# RE01_256KB register map
Vendor: Renesas Electronics Corporation; Series: RE01; File version: 1.00.01
CPU: CM0PLUS r0p1, little endian, MPU, no FPU, VTOR, 2 interrupt priority bits, 32 interrupts
Registers are 8-bit, read-write, reset 0x0 unless marked. A register's access mark holds for its fields unless they carry their own. Offsets are from the block's base; [hi:lo] are bit positions; {n}, {i} and the like mark numbered series; 'fields as' and 'values as' point back to an identical list; <NAME> marks a mode.

## SYSC — System Control
Base 0x4001E000
0x0C SBYCR 16-bit — Standby Control Register
  [15] SSBY — Software Standby Mode Select
    0=Sleep mode; 1=Software Standby mode
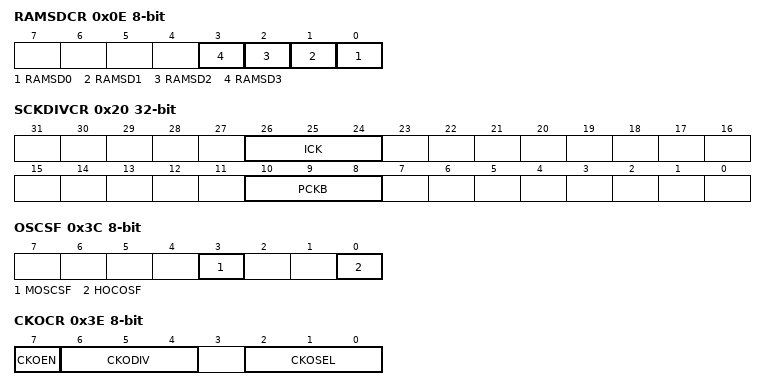
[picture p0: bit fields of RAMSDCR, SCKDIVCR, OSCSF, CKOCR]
0x0E RAMSDCR — RAM Cutoff Control Register
  [all] fields
    0=Does not cut off the power supply to SRAM during software standby mode (SRAM values: retained); 1=Cut off the power supply to SRAM during software standby mode (SRAM values: undefined)
  [n] RAMSD{n} (n=0..3) — SRAM Cutoff in Software Standby Mode
0x1C MSTPCRA 32-bit reset 0xFFBFFFFF — Module Stop Control Register A
  [22] MSTPA22 — DMAC and DTC Module Stop
    0=Cancel the module-stop state; 1=Enter the module-stop state
0x20 SCKDIVCR 32-bit — System Clock Division Control Register
  [26:24] ICK — System Clock (ICLK) Select/Peripheral Module Clock (PCLKA) Select
    0=x 1/1; 1=x 1/2; 2=x 1/4; 3=x 1/8; 4=x 1/16; 5=x 1/32; 6=x 1/64; other=Others (Settings prohibited)
  [10:8] PCKB — Peripheral Module Clock B (PCLKB) Select
    values as ICK
0x26 SCKSCR reset 0x1 — System Clock Source Control Register
  [2:0] CKSEL — Clock Source Select
    0=HOCO; 1=MOCO; 2=LOCO; 3=Main clock oscillator (MOSC); 4=Sub-clock oscillator (SOSC)
0x32 MOSCCR reset 0x1 — Main Clock Oscillator Control Register
  [0] MOSTP — Main Clock Oscillator Stop
    0=Operate the main clock oscillator; 1=Stop the main clock oscillator
0x36 HOCOCR (reset mask 0xFE) — High-Speed On-Chip Oscillator Control Register
  [0] HCSTP — HOCO Stop
    0=Operate the HOCO clock; 1=Stop the HOCO clock
0x37 HOCOMCR (reset mask 0xFE) — High-Speed On-Chip Oscillator Mode Control Register
  [1:0] HCFRQ — HOCO Oscillation Frequency Setting
    0=24 MHz; 1=32 MHz; 2=48 MHz; 3=64 MHz
0x38 MOCOCR — Middle-Speed On-Chip Oscillator Control Register
  [0] MCSTP — MOCO Stop
    0=MOCO clock is operating; 1=MOCO clock is stopped
0x39 FLLCR1 — FLL Control Register1
  [0] FLLEN — FLL Enable
    0=FLL function is disabled; 1=FLL function is enabled
0x3C OSCSF ro (reset mask 0xFE) — Oscillation Stabilization Flag Register
  [3] MOSCSF — Main Clock Oscillation Stabilization Flag
    0=The main clock oscillator is stopped (MOSTP = 1) or is not yet stable; 1=The main clock oscillator is stable, so is available for use as the system clock
  [0] HOCOSF — HOCO Clock Oscillation Stabilization Flag
    0=The HOCO clock is stopped or is not yet stable; 1=The HOCO clock is stable, so is available for use as the system clock
0x3D CKO32CR — Clock Output 32-kHz Control Register
  [7] CKO32EN — Clock Output 32-kHz Enable
    0=Disable clock output for 32 kHz; 1=Enable clock output for 32 kHz
0x3E CKOCR — Clock Out Control Register
  [7] CKOEN — Clock Out Enable
    0=Disable clock out; 1=Enable clock out
  [6:4] CKODIV — Clock Output Frequency Division Ratio
    0=x 1/1; 1=x 1/2; 2=x 1/4; 3=x 1/8; 4=x 1/16; 5=x 1/32; 6=x 1/64; 7=x 1/128
  [2:0] CKOSEL — Clock Out Source Select
    0=HOCO; 1=MOCO; 2=LOCO; 3=MOSC; 4=SOSC; 5=CCC_2K; other=Others (Setting prohibited)
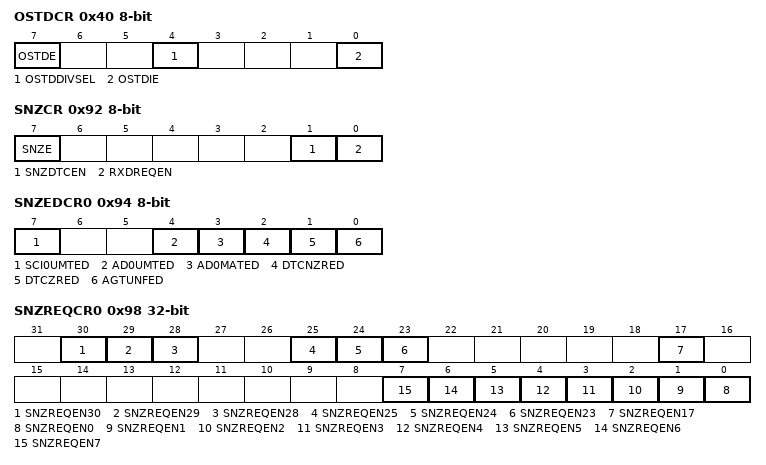
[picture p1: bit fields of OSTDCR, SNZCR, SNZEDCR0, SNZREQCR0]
0x40 OSTDCR — Oscillation Stop Detection Control Register
  [7] OSTDE — Oscillation Stop Detection Function Enable
    0=Disable oscillation stop detection function; 1=Enable oscillation stop detection function
  [4] OSTDDIVSEL — Oscillation Stop Detection Main Clock Frequency Select
    0=8 MHz ≤ frequency of the main clock oscillator ≤ 16 MHz; 1=16 MHz < frequency of the main clock oscillator
  [0] OSTDIE — Oscillation Stop Detection Interrupt Enable
    0=Disable oscillation stop detection interrupt (do not notify the POE); 1=Enable oscillation stop detection interrupt (notify the POE)
0x41 OSTDSR — Oscillation Stop Detection Status Register
  [0] OSTDF — Oscillation Stop Detection Flag
    0=Main clock oscillation stop not detected; 1=Main clock oscillation stop detected
0x92 SNZCR — Snooze Control Register
  [7] SNZE — Snooze mode Enable
    0=Disable Snooze mode; 1=Enable Snooze mode
  [1] SNZDTCEN — DTC Enable in Snooze mode
    0=Disable DTC operation; 1=Enable DTC operation
  [0] RXDREQEN — RXD0 Snooze Request Enable
    0=Ignore RXD0 falling edge in Software Standby mode; 1=Detect RXD0 falling edge in Software Standby mode
0x94 SNZEDCR0 — Snooze End Control Register 0
  [all] fields
    0=Disable the snooze end request; 1=Enable the snooze end request
  [7] SCI0UMTED — SCI0 Address Mismatch Snooze End Enable
  [4] AD0UMTED — AD Compare Mismatch Snooze End Enable
  [3] AD0MATED — AD Compare Match Snooze End Enable
  [2] DTCNZRED — Not Last DTC Transmission Completion Snooze End Enable
  [1] DTCZRED — Last DTC Transmission Completion Snooze End Enable
  [0] AGTUNFED — AGT1 Underflow Snooze End Enable
0x98 SNZREQCR0 32-bit — Snooze Request Control Register 0
  [all] fields
    0=Disable the snooze request; 1=Enable the snooze request
  [30] SNZREQEN30 — Enable AGT0 compare match A snooze request
  [29] SNZREQEN29 — Enable AGT1 compare match A snooze request
  [28] SNZREQEN28 — Enable AGT1 underflow snooze request
  [25] SNZREQEN25 — Enable RTC period snooze request
  [24] SNZREQEN24 — Enable RTC alarm snooze request
  [23] SNZREQEN23 — AGTW0 compare match A snooze request
  [17] SNZREQEN17 — Enable KINT snooze request
  [n] SNZREQEN{n} (n=0..7) — Enable IRQ{n} pin snooze request
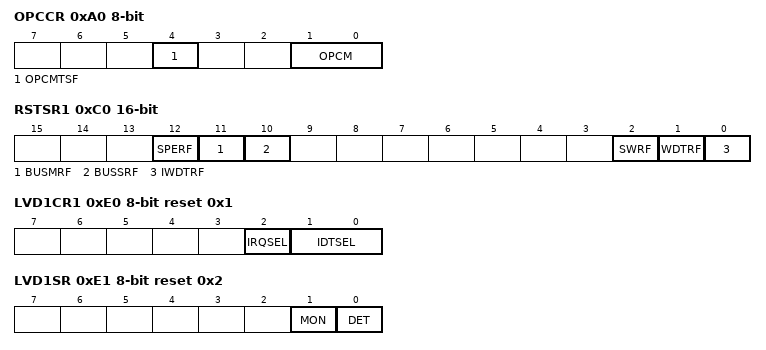
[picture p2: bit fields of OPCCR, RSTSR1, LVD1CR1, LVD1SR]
0xA0 OPCCR — Operating Power Control Register
  [4] OPCMTSF ro — Operating power control mode (High-Speed / Low-Speed mode) transition state flag
    0=Transition completed; 1=During transition
  [1:0] OPCM — Operating power control mode selection
    0=High-speed mode; 3=Low-speed mode; other=Others (Setting prohibited)
0xA2 MOSCWTCR reset 0x5 — Main Clock Oscillator Wait Control Register
  [3:0] MSTS — Main Clock Oscillator Wait Time Setting
    0=Setting prohibited; 1=Wait time = 2 cycles; 2=Wait time = 5 cycles; 3=Wait time = 13 cycles; 4=Wait time = 29 cycles; 5=Wait time = 61 cycles; 6=Wait time = 125 cycles; 7=Wait time = 253 cycles; 8=Wait time = 509 cycles; 9=Wait time = 1021 cycles; other=Others (Setting prohibited)
0xC0 RSTSR1 16-bit (reset mask 0xE3F8) — Reset Status Register 1
  [12] SPERF — CPU Stack Pointer Error Reset Detect Flag
    0=CPU stack pointer error reset not detected; 1=CPU stack pointer error reset detected
  [11] BUSMRF — Bus Master MPU Error Reset Detect Flag
    0=Bus master MPU error reset not detected; 1=Bus master MPU error reset detected
  [10] BUSSRF — Bus Slave MPU Error Reset Detect Flag
    0=Bus slave MPU error reset not detected; 1=Bus slave MPU error reset detected
  [2] SWRF — Software Reset Detect Flag
    0=Software reset not detected; 1=Software reset detected
  [1] WDTRF — Watchdog Timer Reset Detect Flag
    0=Watchdog timer reset not detected; 1=Watchdog timer reset detected
  [0] IWDTRF — Independent Watchdog Timer Reset Detect Flag
    0=Independent watchdog timer reset not detected; 1=Independent watchdog timer reset detected
0xE0 LVD1CR1 reset 0x1 — Voltage Monitor 1 Circuit Control Register
  [2] IRQSEL — Voltage Monitor 1 Interrupt Type Select
    0=Non-maskable interrupt; 1=Maskable interrupt
  [1:0] IDTSEL — Voltage Monitor 1 Interrupt Generation Condition Select
    0=When VCC >= Vdet1 (rise) is detected; 1=When VCC < Vdet1 (fall) is detected; 2=When fall and rise are detected; 3=Settings prohibited
0xE1 LVD1SR reset 0x2 — Voltage Monitor 1 Circuit Status Register
  [1] MON ro — Voltage Monitor 1 Signal Monitor Flag
    0=VCC < Vdet1; 1=VCC >= Vdet1 or MON is disabled
  [0] DET — Voltage Monitor 1 Voltage Variation Detection Flag
    0=Not detected; 1=Vdet1 crossing is detected
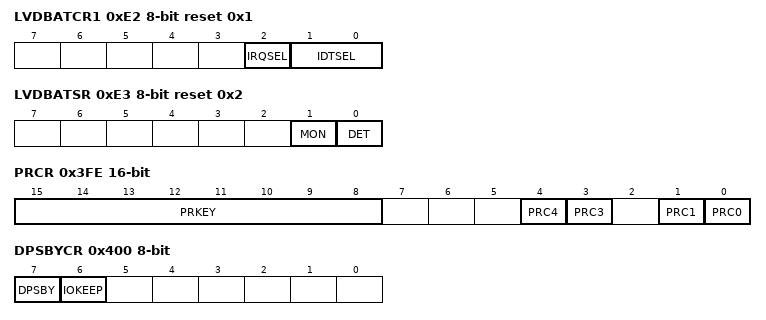
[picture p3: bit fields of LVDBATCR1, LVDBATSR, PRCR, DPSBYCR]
0xE2 LVDBATCR1 reset 0x1 — Voltage Monitor BAT Circuit Control Register 1
  [2] IRQSEL — Voltage Monitor BAT Interrupt Type Select
    0=Non-maskable interrupt; 1=Maskable interrupt
  [1:0] IDTSEL — Voltage Monitor BAT Interrupt Generation Condition Select
    0=When VBAT_EHC>= VdetBAT (rise) is detected; 1=When VBAT_EHC < VdetBAT (fall) is detected; 2=When fall and rise are detected; 3=Settings prohibited
0xE3 LVDBATSR reset 0x2 — Voltage Monitor BAT Circuit Status Register
  [1] MON ro — Voltage Monitor BAT Signal Monitor Flag
    0=VBAT_EHC < VdetBAT; 1=VBAT_EHC>= VdetBAT or MON is disabled
  [0] DET — Voltage Monitor BAT Voltage Variation Detection Flag
    0=Not detected; 1=VdetBAT crossing is detected
0x140 FSTPCR — Function Stop Control Register
  [7] DBGSTP — Debug function stop
    0=Disable; 1=Enable (power-saving functions are enabled)
0x3FE PRCR 16-bit — Protect Register
  [15:8] PRKEY wo — PRC Key Code
  [4] PRC4
    0=Disable writes; 1=Enable writes
  [3] PRC3 — Enable writing to the registers related to the LVD
    0=Disable writes; 1=Enable writes
  [1] PRC1 — Enable writing to the registers related to the functions for reducing power consumption
    0=Disable writes; 1=Enable writes
  [0] PRC0 — Enable writing to the registers related to the clock generation circuit
    0=Disable writes; 1=Enable writes
0x400 DPSBYCR — Deep Software Standby Control Register
  [7] DPSBY — Deep Software Standby Mode Selection
    0=Sleep mode (SBYCR.SSBY=0) / Software Standby mode (SBYCR.SSBY=1); 1=Sleep mode (SBYCR.SSBY=0) / Deep Software Standby mode (SBYCR.SSBY=1)
  [6] IOKEEP — I/O Port Rentention
    0=When the Deep Software Standby mode is canceled, clear the I/O port pins to the reset state; 1=When the Deep Software Standby mode is canceled, keep the I/O port pins in the same state as in Deep Software Standby mode
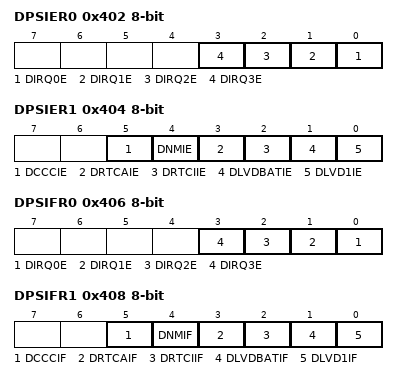
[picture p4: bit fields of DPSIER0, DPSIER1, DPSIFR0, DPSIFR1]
0x402 DPSIER0 — Deep Software Standby Interrupt Enable Register 0
  [all] fields
    0=Cancelling Deep Software Standby mode is disabled; 1=Cancelling Deep Software Standby mode is enabled
  [n] DIRQ{n}E (n=0..3) — IRQ{n}_DS Pin Enable
0x404 DPSIER1 — Deep Software Standby Interrupt Enable Register 1
  [all] fields
    values as the fields of DPSIER0
  [5] DCCCIE — CCC Periodic Interrupt and WUPT Enable
  [4] DNMIE — NMI Pin Enable
  [3] DRTCAIE — RTC Alarm Interrupt Enable
  [2] DRTCIIE — RTC Cycle Interrupt Enable
  [1] DLVDBATIE — LVDBAT Interrupt Enable
  [0] DLVD1IE — LVD1 Interrupt Enable
0x406 DPSIFR0 — Deep Software Standby Interrupt Flag Register 0
  [all] fields
    0=The cancel request is not generated; 1=The cancel request is generated
  [n] DIRQ{n}E (n=0..3) — IRQ{n}_DS Pin Deep Software Standby Cancel Flag
0x408 DPSIFR1 — Deep Software Standby Interrupt Flag Register 1
  [all] fields
    values as the fields of DPSIFR0
  [5] DCCCIF — CCC Periodic Interrupt Deep Software Standby Cancel Flag
  [4] DNMIF — NMI Pin Deep Software Standby Cancel Flag
  [3] DRTCAIF — RTC Alarm Interrupt Deep Software Standby Cancel Flag
  [2] DRTCIIF — RTC Deep Software Standby Cancel Flag
  [1] DLVDBATIF — LVDBAT Deep Software Standby Cancel Flag
  [0] DLVD1IF — LVD1 Deep Software Standby Cancel Flag
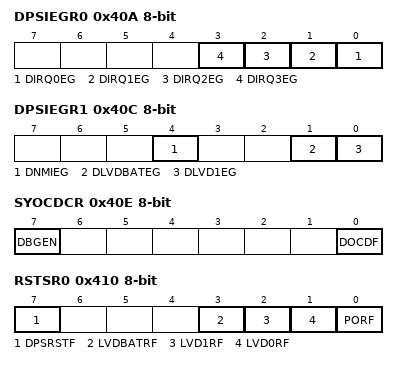
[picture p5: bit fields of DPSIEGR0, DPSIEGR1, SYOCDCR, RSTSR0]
0x40A DPSIEGR0 — Deep Software Standby Interrupt Edge Register 0
  [all] fields
    0=A cancel request is generated at a falling edge; 1=A cancel request is generated at a rising edge
  [n] DIRQ{n}EG (n=0..3) — IRQ{n}_DS Pin Edge Select
0x40C DPSIEGR1 — Deep Software Standby Interrupt Edge Register 1
  [4] DNMIEG — NMI Pin Edge Select
    0=Generate cancel request on falling edge on the NMI pin; 1=Generate cancel request on rising edge on the NMI pin
  [1] DLVDBATEG — LVDBAT Edge Select
    0=Generate cancel request when VBAT_EHC < VdetBAT (voltage fall) is detected; 1=Generate cancel request when VBAT_EHC ≥ VdetBAT (voltage rise) is detected
  [0] DLVD1EG — LVD1 Edge Select
    0=Generate cancel request when VCC < Vdet1; 1=Generate cancel request when VCC ≥ Vdet1 (voltage rise) is detected
0x40E SYOCDCR (reset mask 0xFE) — System Control OCD Control Register
  [7] DBGEN — Debugger Enable bit
    0=On-chip debugger is disabled; 1=On-chip debugger is enabled
  [0] DOCDF — Deep Software Standby OCD flag
    0=DBIRQ is not generated; 1=DBIRQ is generated
0x410 RSTSR0 (reset mask 0x70) — Reset Status Register 0
  [7] DPSRSTF — Deep Software Standby Reset Flag
    0=Deep software standby mode cancellation not requested by an interrupt; 1=Deep software standby mode cancellation requested by an interrupt
  [3] LVDBATRF — Voltage Monitor BAT Reset Detect Flag
    0=Voltage monitor BAT reset undetected; 1=Voltage monitor BAT reset detected
  [2] LVD1RF — Voltage Monitor 1 Reset Detect Flag
    0=Voltage monitor 1 reset not detected; 1=Voltage monitor 1 reset detected
  [1] LVD0RF — Voltage Monitor 0 Reset Detect Flag
    0=Voltage monitor 0 reset not detected; 1=Voltage monitor 0 reset detected
  [0] PORF — Power-On Reset Detect Flag
    0=Power-on reset not detected; 1=Power-on reset detected
0x411 RSTSR2 (reset mask 0xFE) — Reset Status Register 2
  [0] CWSF — Cold/Warm Start Determination Flag
    0=Cold start; 1=Warm start
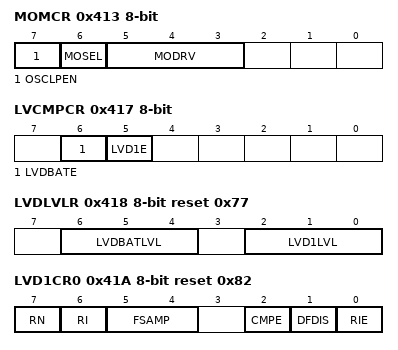
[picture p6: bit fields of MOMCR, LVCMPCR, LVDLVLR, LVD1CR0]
0x413 MOMCR — Main Clock Oscillator Mode Oscillation Control Register
  [7] OSCLPEN — Main Clock Oscillator Low Consumption Oscillation Function Enable
    0=Disable; 1=Enable
  [6] MOSEL — Main Clock Oscillator Switching
    0=Resonator; 1=External clock input
  [5:3] MODRV — Main Clock Oscillator Drive Capability Switching
0x416 FWEPROR reset 0x2 — Flash Write Erase Protect Register
  [1:0] FLWE — Flash Write Erase Enable
    0=Programming and erasing are disabled; 1=Programming and erasing are enabled; 2=Programming and erasing are disabled; 3=Programming and erasing are disabled
0x417 LVCMPCR — Voltage Monitor Circuit Control Register
  [6] LVDBATE — Voltage Detection BAT Enable
    0=Voltage detection BAT circuit disabled; 1=Voltage detection BAT circuit enabled
  [5] LVD1E — Voltage Detection 1 Enable
    0=Voltage detection 1 circuit disabled; 1=Voltage detection 1 circuit enabled
0x418 LVDLVLR reset 0x77 — Voltage Detection Level Select Register
  [6:4] LVDBATLVL — Voltage Detection BAT Level Select
    3=VdetBAT_5; 4=VdetBAT_7; 5=VdetBAT_9; 6=VdetBAT_B; 7=VdetBAT_D; other=Others (Setting prohibited)
  [2:0] LVD1LVL — Voltage Detection 1 Level Select
    0=Vdet1_0; 1=Vdet1_1; 2=Vdet1_3; 3=Vdet1_5; 4=Vdet1_7; 5=Vdet1_9; 6=Vdet1_B; 7=Vdet1_D
0x41A LVD1CR0 reset 0x82 — Voltage Monitor 1 Circuit Control Register 0
  [7] RN — Voltage Monitor 1 Reset Negate Select
    0=Negate after a stabilization time (tLVD1) when VCC > Vdet1 is detected; 1=Negate after a stabilization time (tLVD1) on assertion of the LVD1 reset
  [6] RI — Voltage Monitor 1 Circuit Mode Select
    0=Generate voltage monitor 1 interrupt on Vdet1 crossing; 1=Enable voltage monitor 1 reset when the voltage falls to and below Vdet1
  [5:4] FSAMP — Sampling Clock Select
    0=1/2 LOCO frequency; 1=1/4 LOCO frequency; 2=1/8 LOCO frequency; 3=1/16 LOCO frequency
  [2] CMPE — Voltage Monitor 1 Circuit Comparison Result Output Enable
    0=Disable voltage monitor 1 circuit comparison result output; 1=Enable voltage monitor 1 circuit comparison result output
  [1] DFDIS — Voltage monitor 1 Digital Filter Disabled Mode Select
    0=Enable the digital filter; 1=Disable the digital filter
  [0] RIE — Voltage Monitor 1 Interrupt/Reset Enable
    0=Disable; 1=Enable
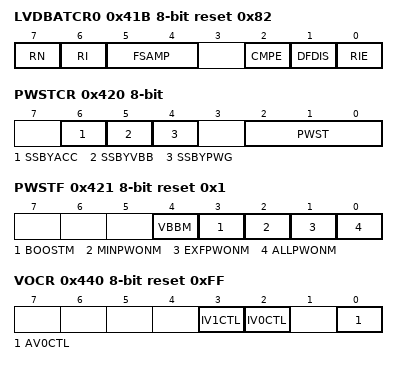
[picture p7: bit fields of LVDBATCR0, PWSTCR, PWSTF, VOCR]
0x41B LVDBATCR0 reset 0x82 — Voltage Monitor BAT Circuit Control Register 0
  [7] RN — Voltage Monitor BAT Reset Negate Select
    0=Negate after a stabilization time (tLVDBAT) when VBAT_EHC > VdetBAT is detected; 1=Negate after a stabilization time (tLVDBAT) on assertion of the LVDBAT reset
  [6] RI — Voltage Monitor BAT Circuit Mode Select
    0=Generate voltage monitor BAT interrupt on VdetBAT crossing; 1=Enable voltage monitor BAT reset when the voltage falls to and below VdetBAT
  [5:4] FSAMP — Sampling Clock Select
    values as LVD1CR0.FSAMP
  [2] CMPE — Voltage Monitor BAT Circuit Comparison Result Output Enable
    0=Disable voltage monitor BAT circuit comparison result output; 1=Enable voltage monitor BAT circuit comparison result output
  [1] DFDIS — Voltage monitor BAT Digital Filter Disabled Mode Select
    0=Enable the digital filter; 1=Disable the digital filter
  [0] RIE — Voltage Monitor BAT Interrupt/Reset Enable
    0=Disable; 1=Enable
0x420 PWSTCR — Power Supply State Control Register
  [6] SSBYACC — Fast transition / return select in software standby mode
    0=Not selects transition to software standby mode and reduction of recovery time; 1=Selects transition to software standby mode under specific conditions and reduction of recovery time
  [5] SSBYVBB — Back bias voltage control selection in software standby mode
    0=Back bias voltage control is not performed in software standby mode; 1=Back bias voltage control is performed in the software standby mode
  [4] SSBYPWG — Select voltage cut-off area in software standby mode
    0=In software standby mode, shut off only the flash power domain (ISO3); 1=In software standby mode, shut off the flash power domain (ISO3) and the power domain (ISO2) for most peripheral functions
  [2:0] PWST — Power Supply State Select
    0=Transition to one of the following modesSwitching high-speed/low-speed modes in normal mode (NORMAL)Software standby modeDeep software standby mode; 1=Transition to all power supply mode (ALLPWON); 2=Transition to exclude-flash power supply mode (EXFPWON); 3=Transition to minimum power supply mode (MINPWON); 4=Transition to normal mode (NORMAL); 5=Transition to boost mode (BOOST); 6=Transition to low leakage current mode (VBB); 7=Setting prohibited
0x421 PWSTF ro reset 0x1 — Power Supply State Flag Register
  [4] VBBM — Low Leakage Current Mode Flag
  [3] BOOSTM — Boost Mode Flag
  [2] MINPWONM — Minimum Power Supply Mode Flag
  [1] EXFPWONM — Exclude-flash Power Supply mode Flag
  [0] ALLPWONM — All Power Supply Mode Flag
0x428 LDOCR — Regulator Control Register
  [3] LDOCUT — Regulator (LDO) stop
    0=LDO works Supply LDO output voltage to internal circuit; 1=LDO stops Supply externally applied voltage to internal circuit
0x440 VOCR reset 0xFF — Power Supply Open Control Register
  [3] IV1CTL — IOVCC1 Supply Control
    0=The undefined value is propagated from the IOVCC1 power domain to other power domains; 1=The undefined value is not propagated from the IOVCC1 power domain to other power domains
  [2] IV0CTL — IOVCC0 Supply Control
    0=The undefined value is propagated from the IOVCC0 power domain to other power domains; 1=The undefined value is not propagated from the IOVCC0 power domain to other power domains
  [0] AV0CTL — AVCC0 Supply Control
    0=The undefined value is propagated from the AVCC0 power domain to other power domains; 1=The undefined value is not propagated from the AVCC0 power domain to other power domains
0x480 SOSCCR reset 0x1 — Sub-Clock Oscillator Control Register
  [0] SOSTP — Sub Clock Oscillator Stop
    0=Operate the sub-clock oscillator; 1=Stop the sub-clock oscillator
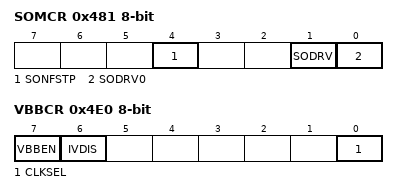
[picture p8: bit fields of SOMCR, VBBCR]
0x481 SOMCR — Sub-Clock Oscillator Mode Control Register
  [4] SONFSTP — Sub-Clock Oscillator Noise Filter Disable
    0=Noise filter is enabled; 1=Noise filter is disabled
  [1] SODRV — Sub-Clock Oscillator Drive Capability Switching
  [0] SODRV0 — Sub-Clock Oscillator Drive Capability Switching
0x490 LOCOCR — Low-Speed On-Chip Oscillator Control Register
  [0] LCSTP — LOCO Stop
    0=Operate the LOCO clock; 1=Stop the LOCO clock
0x4E0 VBBCR (reset mask 0x7F) — Back Bias Voltage Control Register
  [7] VBBEN — Back Bias Voltage Control (VBBC) Enable
    0=Disable the VBBC circuit operation; 1=Enable the VBBC circuit operation
  [6] IVDIS — Internal Voltage Discharge
    0=The internal voltage is not discharged; 1=The internal voltage is discharged
  [0] CLKSEL — Back Bias Voltage Control (VBBC) Clock Select
    0=LOCO clock; 1=SOSC clock
0x4E1 VBBST ro — Back Bias Voltage Status Register
  [0] VBBSTUP — Back Bias Voltage Control (VBBC) Initial Setup Complete Flag
    0=During the VBBC circuit stop or VBBC setup; 1=VBBC initial setup completed
